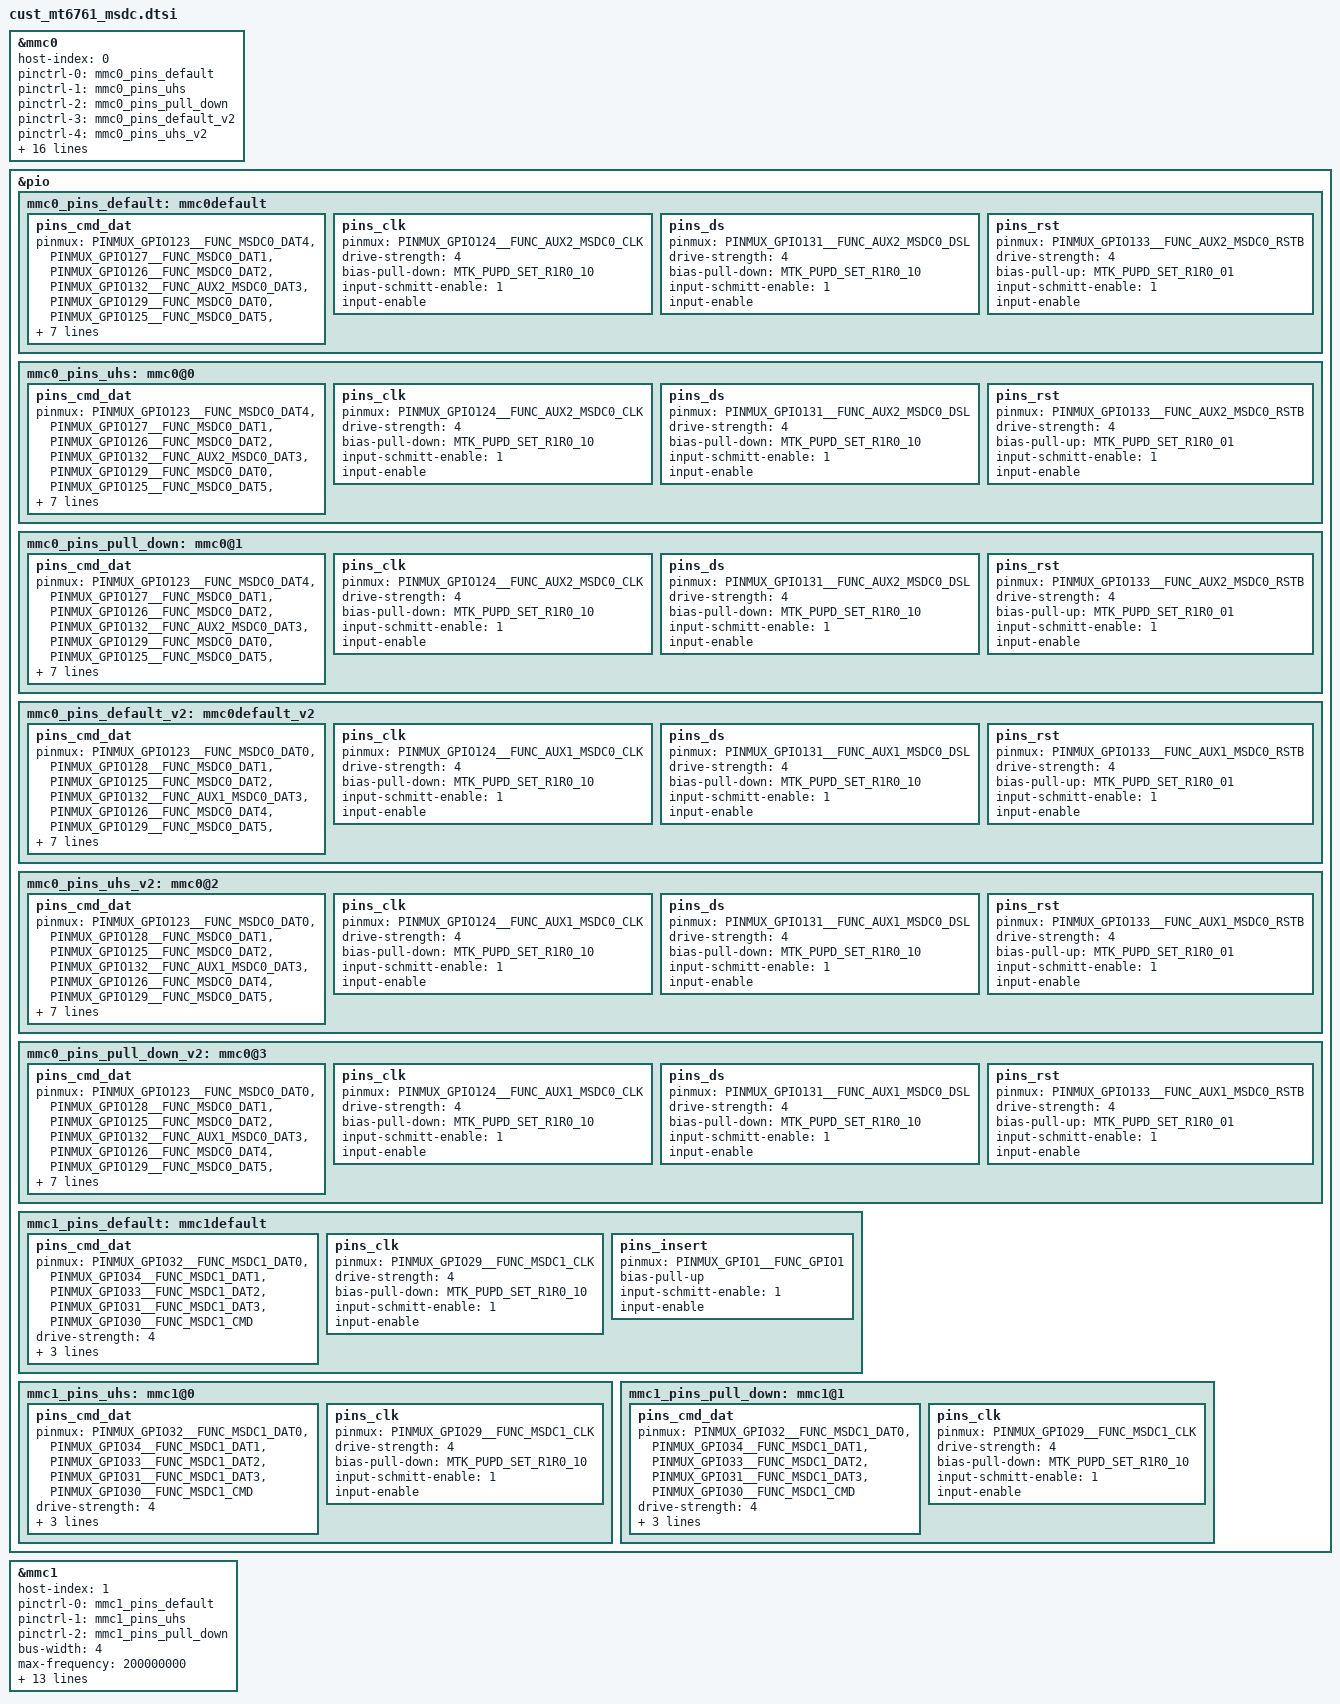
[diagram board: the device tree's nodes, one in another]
// SPDX-License-Identifier: (GPL-2.0 OR MIT)
/*
 * Copyright (c) 2019 MediaTek Inc.
 */
/********************************************
 * MT6761 MSDC DTSI File
 ********************************************/
#include <dt-bindings/gpio/gpio.h>

&mmc0 {
	host-index = <0>;
	status = "okay";
	pinctrl-names = "default", "state_uhs", "pull_down",
		"default_v2", "state_uhs_v2", "pull_down_v2";
	pinctrl-0 = <&mmc0_pins_default>;
	pinctrl-1 = <&mmc0_pins_uhs>;
	pinctrl-2 = <&mmc0_pins_pull_down>;
	pinctrl-3 = <&mmc0_pins_default_v2>;
	pinctrl-4 = <&mmc0_pins_uhs_v2>;
	pinctrl-5 = <&mmc0_pins_pull_down_v2>;
	bus-width = <8>;
	max-frequency = <200000000>;
	ocr-voltage = <0x00030000>;
	cap-mmc-highspeed;
	mmc-ddr-1_8v;
	mmc-hs200-1_8v;
	mmc-hs400-1_8v;
	no-sdio;
	no-sd;
	hs400-ds-delay = <0x12814>;
	vmmc-supply = <&mt_pmic_vemc_ldo_reg>;
	non-removable;
	supports-cqe;
	dvfsrc-vcore-supply = <&dvfsrc_vcore>;
	req-vcore = <650000>;
};

&pio {
	mmc0_pins_default: mmc0default {
		pins_cmd_dat {
			pinmux = <PINMUX_GPIO123__FUNC_MSDC0_DAT4>,
				 <PINMUX_GPIO127__FUNC_MSDC0_DAT1>,
				 <PINMUX_GPIO126__FUNC_MSDC0_DAT2>,
				 <PINMUX_GPIO132__FUNC_AUX2_MSDC0_DAT3>,
				 <PINMUX_GPIO129__FUNC_MSDC0_DAT0>,
				 <PINMUX_GPIO125__FUNC_MSDC0_DAT5>,
				 <PINMUX_GPIO128__FUNC_MSDC0_DAT6>,
				 <PINMUX_GPIO130__FUNC_AUX2_MSDC0_DAT7>,
				 <PINMUX_GPIO122__FUNC_AUX2_MSDC0_CMD>;
			drive-strength = <4>;
			bias-pull-up = <MTK_PUPD_SET_R1R0_01>;
			input-schmitt-enable = <1>;
			input-enable;
		};
		pins_clk {
			pinmux = <PINMUX_GPIO124__FUNC_AUX2_MSDC0_CLK>;
			drive-strength = <4>;
			bias-pull-down = <MTK_PUPD_SET_R1R0_10>;
			input-schmitt-enable = <1>;
			input-enable;
		};
		pins_ds {
			pinmux = <PINMUX_GPIO131__FUNC_AUX2_MSDC0_DSL>;
			drive-strength = <4>;
			bias-pull-down = <MTK_PUPD_SET_R1R0_10>;
			input-schmitt-enable = <1>;
			input-enable;

		};
		pins_rst {
			pinmux = <PINMUX_GPIO133__FUNC_AUX2_MSDC0_RSTB>;
			drive-strength = <4>;
			bias-pull-up = <MTK_PUPD_SET_R1R0_01>;
			input-schmitt-enable = <1>;
			input-enable;
		};
	};
	mmc0_pins_uhs: mmc0@0{
		pins_cmd_dat {
			pinmux = <PINMUX_GPIO123__FUNC_MSDC0_DAT4>,
				 <PINMUX_GPIO127__FUNC_MSDC0_DAT1>,
				 <PINMUX_GPIO126__FUNC_MSDC0_DAT2>,
				 <PINMUX_GPIO132__FUNC_AUX2_MSDC0_DAT3>,
				 <PINMUX_GPIO129__FUNC_MSDC0_DAT0>,
				 <PINMUX_GPIO125__FUNC_MSDC0_DAT5>,
				 <PINMUX_GPIO128__FUNC_MSDC0_DAT6>,
				 <PINMUX_GPIO130__FUNC_AUX2_MSDC0_DAT7>,
				 <PINMUX_GPIO122__FUNC_AUX2_MSDC0_CMD>;
			drive-strength = <4>;
			bias-pull-up = <MTK_PUPD_SET_R1R0_01>;
			input-schmitt-enable = <1>;
			input-enable;
		};
		pins_clk {
			pinmux = <PINMUX_GPIO124__FUNC_AUX2_MSDC0_CLK>;
			drive-strength = <4>;
			bias-pull-down = <MTK_PUPD_SET_R1R0_10>;
			input-schmitt-enable = <1>;
			input-enable;
		};
		pins_ds {
			pinmux = <PINMUX_GPIO131__FUNC_AUX2_MSDC0_DSL>;
			drive-strength = <4>;
			bias-pull-down = <MTK_PUPD_SET_R1R0_10>;
			input-schmitt-enable = <1>;
			input-enable;
		};
		pins_rst {
			pinmux = <PINMUX_GPIO133__FUNC_AUX2_MSDC0_RSTB>;
			drive-strength = <4>;
			bias-pull-up = <MTK_PUPD_SET_R1R0_01>;
			input-schmitt-enable = <1>;
			input-enable;
		};
	};
	mmc0_pins_pull_down: mmc0@1{
		pins_cmd_dat {
			pinmux = <PINMUX_GPIO123__FUNC_MSDC0_DAT4>,
				 <PINMUX_GPIO127__FUNC_MSDC0_DAT1>,
				 <PINMUX_GPIO126__FUNC_MSDC0_DAT2>,
				 <PINMUX_GPIO132__FUNC_AUX2_MSDC0_DAT3>,
				 <PINMUX_GPIO129__FUNC_MSDC0_DAT0>,
				 <PINMUX_GPIO125__FUNC_MSDC0_DAT5>,
				 <PINMUX_GPIO128__FUNC_MSDC0_DAT6>,
				 <PINMUX_GPIO130__FUNC_AUX2_MSDC0_DAT7>,
				 <PINMUX_GPIO122__FUNC_AUX2_MSDC0_CMD>;
			drive-strength = <4>;
			bias-pull-down = <MTK_PUPD_SET_R1R0_10>;
			input-schmitt-enable = <1>;
			input-enable;
		};
		pins_clk {
			pinmux = <PINMUX_GPIO124__FUNC_AUX2_MSDC0_CLK>;
			drive-strength = <4>;
			bias-pull-down = <MTK_PUPD_SET_R1R0_10>;
			input-schmitt-enable = <1>;
			input-enable;
		};
		pins_ds {
			pinmux = <PINMUX_GPIO131__FUNC_AUX2_MSDC0_DSL>;
			drive-strength = <4>;
			bias-pull-down = <MTK_PUPD_SET_R1R0_10>;
			input-schmitt-enable = <1>;
			input-enable;
		};
		pins_rst {
			pinmux = <PINMUX_GPIO133__FUNC_AUX2_MSDC0_RSTB>;
			drive-strength = <4>;
			bias-pull-up = <MTK_PUPD_SET_R1R0_01>;
			input-schmitt-enable = <1>;
			input-enable;
		};
	};

	mmc0_pins_default_v2: mmc0default_v2 {
		pins_cmd_dat {
			pinmux = <PINMUX_GPIO123__FUNC_MSDC0_DAT0>,
				 <PINMUX_GPIO128__FUNC_MSDC0_DAT1>,
				 <PINMUX_GPIO125__FUNC_MSDC0_DAT2>,
				 <PINMUX_GPIO132__FUNC_AUX1_MSDC0_DAT3>,
				 <PINMUX_GPIO126__FUNC_MSDC0_DAT4>,
				 <PINMUX_GPIO129__FUNC_MSDC0_DAT5>,
				 <PINMUX_GPIO127__FUNC_MSDC0_DAT6>,
				 <PINMUX_GPIO130__FUNC_AUX1_MSDC0_DAT7>,
				 <PINMUX_GPIO122__FUNC_AUX1_MSDC0_CMD>;
			drive-strength = <4>;
			bias-pull-up = <MTK_PUPD_SET_R1R0_01>;
			input-schmitt-enable = <1>;
			input-enable;
		};
		pins_clk {
			pinmux = <PINMUX_GPIO124__FUNC_AUX1_MSDC0_CLK>;
			drive-strength = <4>;
			bias-pull-down = <MTK_PUPD_SET_R1R0_10>;
			input-schmitt-enable = <1>;
			input-enable;
		};
		pins_ds {
			pinmux = <PINMUX_GPIO131__FUNC_AUX1_MSDC0_DSL>;
			drive-strength = <4>;
			bias-pull-down = <MTK_PUPD_SET_R1R0_10>;
			input-schmitt-enable = <1>;
			input-enable;

		};
		pins_rst {
			pinmux = <PINMUX_GPIO133__FUNC_AUX1_MSDC0_RSTB>;
			drive-strength = <4>;
			bias-pull-up = <MTK_PUPD_SET_R1R0_01>;
			input-schmitt-enable = <1>;
			input-enable;
		};
	};
	mmc0_pins_uhs_v2: mmc0@2 {
		pins_cmd_dat {
			pinmux = <PINMUX_GPIO123__FUNC_MSDC0_DAT0>,
				 <PINMUX_GPIO128__FUNC_MSDC0_DAT1>,
				 <PINMUX_GPIO125__FUNC_MSDC0_DAT2>,
				 <PINMUX_GPIO132__FUNC_AUX1_MSDC0_DAT3>,
				 <PINMUX_GPIO126__FUNC_MSDC0_DAT4>,
				 <PINMUX_GPIO129__FUNC_MSDC0_DAT5>,
				 <PINMUX_GPIO127__FUNC_MSDC0_DAT6>,
				 <PINMUX_GPIO130__FUNC_AUX1_MSDC0_DAT7>,
				 <PINMUX_GPIO122__FUNC_AUX1_MSDC0_CMD>;
			drive-strength = <4>;
			bias-pull-up = <MTK_PUPD_SET_R1R0_01>;
			input-schmitt-enable = <1>;
			input-enable;
		};
		pins_clk {
			pinmux = <PINMUX_GPIO124__FUNC_AUX1_MSDC0_CLK>;
			drive-strength = <4>;
			bias-pull-down = <MTK_PUPD_SET_R1R0_10>;
			input-schmitt-enable = <1>;
			input-enable;
		};
		pins_ds {
			pinmux = <PINMUX_GPIO131__FUNC_AUX1_MSDC0_DSL>;
			drive-strength = <4>;
			bias-pull-down = <MTK_PUPD_SET_R1R0_10>;
			input-schmitt-enable = <1>;
			input-enable;
		};
		pins_rst {
			pinmux = <PINMUX_GPIO133__FUNC_AUX1_MSDC0_RSTB>;
			drive-strength = <4>;
			bias-pull-up = <MTK_PUPD_SET_R1R0_01>;
			input-schmitt-enable = <1>;
			input-enable;
		};
	};
	mmc0_pins_pull_down_v2: mmc0@3 {
		pins_cmd_dat {
			pinmux = <PINMUX_GPIO123__FUNC_MSDC0_DAT0>,
				 <PINMUX_GPIO128__FUNC_MSDC0_DAT1>,
				 <PINMUX_GPIO125__FUNC_MSDC0_DAT2>,
				 <PINMUX_GPIO132__FUNC_AUX1_MSDC0_DAT3>,
				 <PINMUX_GPIO126__FUNC_MSDC0_DAT4>,
				 <PINMUX_GPIO129__FUNC_MSDC0_DAT5>,
				 <PINMUX_GPIO127__FUNC_MSDC0_DAT6>,
				 <PINMUX_GPIO130__FUNC_AUX1_MSDC0_DAT7>,
				 <PINMUX_GPIO122__FUNC_AUX1_MSDC0_CMD>;
			drive-strength = <4>;
			bias-pull-down = <MTK_PUPD_SET_R1R0_10>;
			input-schmitt-enable = <1>;
			input-enable;
		};
		pins_clk {
			pinmux = <PINMUX_GPIO124__FUNC_AUX1_MSDC0_CLK>;
			drive-strength = <4>;
			bias-pull-down = <MTK_PUPD_SET_R1R0_10>;
			input-schmitt-enable = <1>;
			input-enable;
		};
		pins_ds {
			pinmux = <PINMUX_GPIO131__FUNC_AUX1_MSDC0_DSL>;
			drive-strength = <4>;
			bias-pull-down = <MTK_PUPD_SET_R1R0_10>;
			input-schmitt-enable = <1>;
			input-enable;

		};
		pins_rst {
			pinmux = <PINMUX_GPIO133__FUNC_AUX1_MSDC0_RSTB>;
			drive-strength = <4>;
			bias-pull-up = <MTK_PUPD_SET_R1R0_01>;
			input-schmitt-enable = <1>;
			input-enable;
		};
	};

};

&mmc1 {
	host-index = <1>;
	status = "okay";
	pinctrl-names = "default", "state_uhs", "pull_down";
	pinctrl-0 = <&mmc1_pins_default>;
	pinctrl-1 = <&mmc1_pins_uhs>;
	pinctrl-2 = <&mmc1_pins_pull_down>;
	bus-width = <4>;
	max-frequency = <200000000>;
	ocr-voltage = <0x00030000>;
	cap-sd-highspeed;
	sd-uhs-sdr12;
	sd-uhs-sdr25;
	sd-uhs-sdr50;
	sd-uhs-sdr104;
	sd-uhs-ddr50;
	cd-debounce-delay-ms = <0>;
	cd-gpios = <&pio 1 GPIO_ACTIVE_LOW>;
	vmmc-supply = <&mt_pmic_vmch_ldo_reg>;
	vqmmc-supply = <&mt_pmic_vmc_ldo_reg>;
	no-mmc;
	no-sdio;
};

&pio {
	mmc1_pins_default: mmc1default {
		pins_cmd_dat {
			pinmux = <PINMUX_GPIO32__FUNC_MSDC1_DAT0>,
				<PINMUX_GPIO34__FUNC_MSDC1_DAT1>,
				<PINMUX_GPIO33__FUNC_MSDC1_DAT2>,
				<PINMUX_GPIO31__FUNC_MSDC1_DAT3>,
				<PINMUX_GPIO30__FUNC_MSDC1_CMD>;
			drive-strength = <4>;
			bias-pull-up = <MTK_PUPD_SET_R1R0_01>;
			input-schmitt-enable = <1>;
			input-enable;
		};
		pins_clk {
			pinmux = <PINMUX_GPIO29__FUNC_MSDC1_CLK>;
			drive-strength = <4>;
			bias-pull-down = <MTK_PUPD_SET_R1R0_10>;
			input-schmitt-enable = <1>;
			input-enable;
		};
		pins_insert {
			pinmux = <PINMUX_GPIO1__FUNC_GPIO1>;
			bias-pull-up;
			input-schmitt-enable = <1>;
			input-enable;
		};
	};
	mmc1_pins_uhs: mmc1@0{
		pins_cmd_dat {
			pinmux = <PINMUX_GPIO32__FUNC_MSDC1_DAT0>,
				<PINMUX_GPIO34__FUNC_MSDC1_DAT1>,
				<PINMUX_GPIO33__FUNC_MSDC1_DAT2>,
				<PINMUX_GPIO31__FUNC_MSDC1_DAT3>,
				<PINMUX_GPIO30__FUNC_MSDC1_CMD>;
			drive-strength = <4>;
			bias-pull-up = <MTK_PUPD_SET_R1R0_01>;
			input-schmitt-enable = <1>;
			input-enable;
		};
		pins_clk {
			pinmux = <PINMUX_GPIO29__FUNC_MSDC1_CLK>;
			drive-strength = <4>;
			bias-pull-down = <MTK_PUPD_SET_R1R0_10>;
			input-schmitt-enable = <1>;
			input-enable;
		};
	};
	mmc1_pins_pull_down: mmc1@1{
		pins_cmd_dat {
			pinmux = <PINMUX_GPIO32__FUNC_MSDC1_DAT0>,
				<PINMUX_GPIO34__FUNC_MSDC1_DAT1>,
				<PINMUX_GPIO33__FUNC_MSDC1_DAT2>,
				<PINMUX_GPIO31__FUNC_MSDC1_DAT3>,
				<PINMUX_GPIO30__FUNC_MSDC1_CMD>;
			drive-strength = <4>;
			bias-pull-down = <MTK_PUPD_SET_R1R0_10>;
			input-schmitt-enable = <1>;
			input-enable;
		};
		pins_clk {
			pinmux = <PINMUX_GPIO29__FUNC_MSDC1_CLK>;
			drive-strength = <4>;
			bias-pull-down = <MTK_PUPD_SET_R1R0_10>;
			input-schmitt-enable = <1>;
			input-enable;
		};
	};
};
